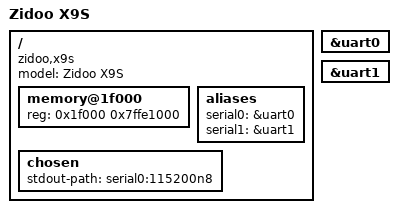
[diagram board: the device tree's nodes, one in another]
/dts-v1/;
#include "rtd1295.dtsi"
/ {
	compatible = "zidoo,x9s", "realtek,rtd1295";
	model = "Zidoo X9S";
	memory@1f000 {
		device_type = "memory";
		reg = <0x1f000 0x7ffe1000>;  
	};
	aliases {
		serial0 = &uart0;
		serial1 = &uart1;
	};
	chosen {
		stdout-path = "serial0:115200n8";
	};
};
&uart0 {
	status = "okay";
};
&uart1 {
	status = "okay";
};
